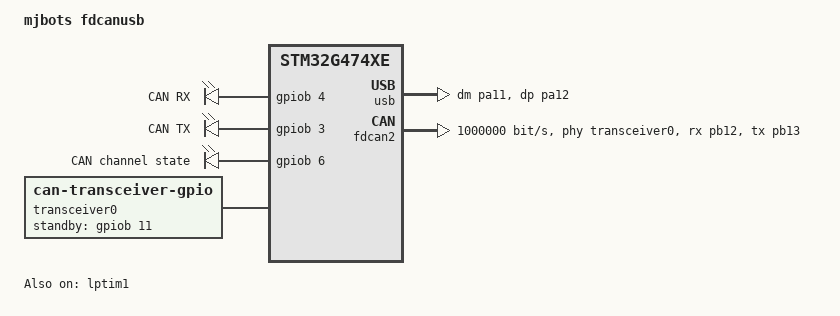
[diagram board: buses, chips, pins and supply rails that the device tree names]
/*
 * Copyright (c) 2025 Filics
 *
 * SPDX-License-Identifier: LicenseRef-Filics
 */

/dts-v1/;
#include <st/g4/stm32g474Xe.dtsi>
#include <st/g4/stm32g474r(b-c-e)tx-pinctrl.dtsi>

/ {
	model = "mjbots fdcanusb" ;
	compatible = "mjbots,fdcanusb";

	chosen {
		zephyr,sram = &sram0;
		zephyr,flash = &flash0;
		zephyr,canbus = &fdcan2;
		zephyr,code-partition = &slot0_partition;
	};

	aliases {
		led0 = &led_can_state;
		led1 = &led_can_tx;
		led2 = &led_can_rx;
	};

	leds: leds {
		compatible = "gpio-leds";
		led_can_rx: led_1 {
			gpios = <&gpiob 4 GPIO_ACTIVE_HIGH>;
			label = "CAN RX";
		};

		led_can_tx: led_2 {
			gpios = <&gpiob 3 GPIO_ACTIVE_HIGH>;
			label = "CAN TX";
		};

		led_can_state: led_3 {
			gpios = <&gpiob 6 GPIO_ACTIVE_HIGH>;
			label = "CAN channel state";
		};
	};
		
	transceiver0: tja1057-can-phy0 {
		compatible = "can-transceiver-gpio";
		standby-gpios = <&gpiob 11 GPIO_ACTIVE_HIGH>;
		max-bitrate = <5000000>;
		#phy-cells = <0>;
	};
};

&clk_hsi {
	/* Internal 16 MHz clock used to drive PLL */
	status = "okay";
};

&clk_hsi48 {
	/* Internal 48 MHz clock used to drive USB */
	status = "okay";
};

/* Adjust the pll for a SYSTEM Clock of 160 MHz  */
&pll {
	div-m = <4>;
	mul-n = <80>;
	div-p = <2>;
	div-q = <4>;
	div-r = <2>;
	clocks = <&clk_hsi>;
	status = "okay";
};

&rcc {
	clocks = <&pll>;
	clock-frequency = <DT_FREQ_M(160)>;
	ahb-prescaler = <1>;
	apb1-prescaler = <1>;
	apb2-prescaler = <1>;
};

stm32_lp_tick_source: &lptim1 {
	clocks = <&rcc STM32_CLOCK_BUS_APB1 0x80000000>,
		 <&rcc STM32_SRC_LSE LPTIM1_SEL(3)>;
	status = "okay";
};


zephyr_udc0: &usb {
	pinctrl-0 = <&usb_dm_pa11 &usb_dp_pa12>;
	pinctrl-names = "default";
	clocks = <&rcc STM32_CLOCK(APB1, 23U)>,
		 <&rcc STM32_SRC_HSI48 CLK48_SEL(0)>;
	status = "okay";
};


&fdcan2 {
	clocks = <&rcc STM32_CLOCK(APB1, 25U)>,
			 <&rcc STM32_SRC_PLL_Q FDCAN_SEL(1)>;
	pinctrl-0 = <&fdcan2_rx_pb12 &fdcan2_tx_pb13>;
	pinctrl-names = "default";

	bitrate = <1000000>;
	bitrate-data = <5000000>;
	sample-point = <800>;
	sample-point-data = <650>;

	clk-divider = <1>;
	status = "okay";
	phys = <&transceiver0>;
};

&flash0 {
	partitions {
		compatible = "fixed-partitions";
		#address-cells = <1>;
		#size-cells = <1>; 

		/* Size: 72 * 1024 = 73728 bytes = 0x12000 */
		boot_partition: partition@0 {
			label = "mcuboot";
			reg = <0x00000000 DT_SIZE_K(72)>; /* End address: 0x12000 */
		};

		/* Size: 220 * 1024 = 225280 bytes = 0x37000 */
		slot0_partition: partition@12000 {
			label = "image-0";
			reg = <0x00012000 DT_SIZE_K(220)>; /* End address: 0x12000 + 0x37000 = 0x49000 */
		};

		/* Size: 220 * 1024 = 225280 bytes = 0x37000 */
		slot1_partition: partition@49000 {
			label = "image-1";
			reg = <0x00049000 DT_SIZE_K(220)>; /* End address: 0x49000 + 0x37000 = 0x80000 */
		};
	};
};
